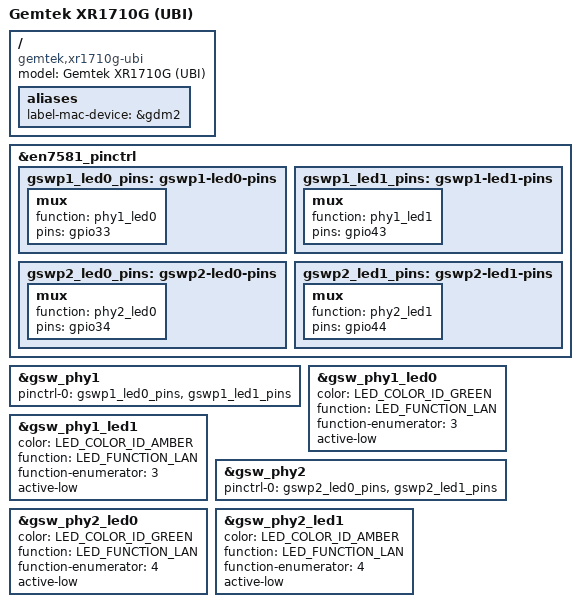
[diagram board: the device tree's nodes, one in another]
// SPDX-License-Identifier: GPL-2.0-or-later OR MIT

/dts-v1/;

#include "an7581-gemtek_w1700k-common.dtsi"

/ {
	model = "Gemtek XR1710G (UBI)";
	compatible = "gemtek,xr1710g-ubi", "airoha,an7581", "airoha,en7581";

	aliases {
		label-mac-device = &gdm2;
	};
};

&en7581_pinctrl {
	/* The lan3/lan4 LEDs are driven by the internal switch PHYs */
	gswp1_led0_pins: gswp1-led0-pins {
		mux {
			function = "phy1_led0";
			pins = "gpio33";
		};
	};

	gswp1_led1_pins: gswp1-led1-pins {
		mux {
			function = "phy1_led1";
			pins = "gpio43";
		};
	};

	gswp2_led0_pins: gswp2-led0-pins {
		mux {
			function = "phy2_led0";
			pins = "gpio34";
		};
	};

	gswp2_led1_pins: gswp2-led1-pins {
		mux {
			function = "phy2_led1";
			pins = "gpio44";
		};
	};
};

&gsw_phy1 {
	pinctrl-names = "gbe-led";
	pinctrl-0 = <&gswp1_led0_pins>, <&gswp1_led1_pins>;
};

&gsw_phy1_led0 {
	status = "okay";
	color = <LED_COLOR_ID_GREEN>;
	function = LED_FUNCTION_LAN;
	function-enumerator = <3>;
	active-low;
};

&gsw_phy1_led1 {
	status = "okay";
	color = <LED_COLOR_ID_AMBER>;
	function = LED_FUNCTION_LAN;
	function-enumerator = <3>;
	active-low;
};

&gsw_phy2 {
	pinctrl-names = "gbe-led";
	pinctrl-0 = <&gswp2_led0_pins>, <&gswp2_led1_pins>;
};

&gsw_phy2_led0 {
	status = "okay";
	color = <LED_COLOR_ID_GREEN>;
	function = LED_FUNCTION_LAN;
	function-enumerator = <4>;
	active-low;
};

&gsw_phy2_led1 {
	status = "okay";
	color = <LED_COLOR_ID_AMBER>;
	function = LED_FUNCTION_LAN;
	function-enumerator = <4>;
	active-low;
};
